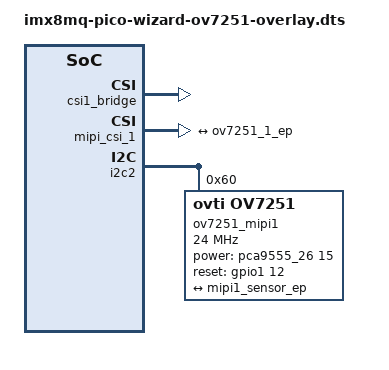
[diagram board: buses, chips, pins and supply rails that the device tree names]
/dts-v1/;
/plugin/;

#include "../imx8mq-pinfunc.h"
#include <dt-bindings/clock/imx8mq-clock.h>
#include <dt-bindings/interrupt-controller/irq.h>
#include <dt-bindings/input/input.h>
#include <dt-bindings/gpio/gpio.h>

/ {

	fragment@0 {
		target = <&csi1_bridge>;
		__overlay__ {
			status = "okay";
		};
	};

	fragment@1 {
		target = <&mipi_csi_1>;
		__overlay__ {
			status = "okay";
			#address-cells = <1>;
			#size-cells = <0>;

			port {
				mipi1_sensor_ep: endpoint@0 {
					remote-endpoint = <&ov7251_1_ep>;
					data-lanes = <1>;
					csis-hs-settle = <13>;
					csis-clk-settle = <2>;
					csis-wclk;
				};
			};
		};
	};

	fragment@2 {
		target = <&i2c2>;
		__overlay__ {
			#address-cells = <1>;
			#size-cells = <0>;
			status = "okay";

			ov7251_mipi1: ov7251@60 {
				compatible = "ovti,ov7251";
				reg = <0x60>;
				status = "okay";

				pinctrl-names = "default";
				pinctrl-0 = <&pinctrl_csi1>;
				clocks = <&clk IMX8MQ_CLK_CLKO2>;
				clock-names = "xclk";
				clock-frequency = <24000000>;

				csi_id = <0>;
				power-gpios = <&pca9555_26 15 GPIO_ACTIVE_HIGH>;
				reset-gpios = <&gpio1 12 GPIO_ACTIVE_HIGH>;

				port {
					ov7251_1_ep: endpoint {
						//clock-lanes = <1>;
						data-lanes = <0>;
						remote-endpoint = <&mipi1_sensor_ep>;
					};
				};
			};
		};
	};
};
